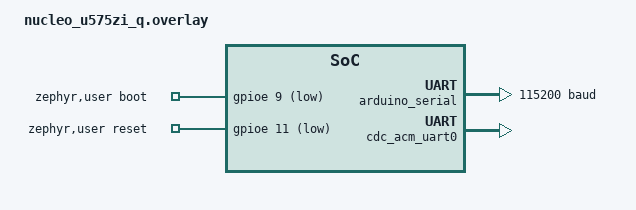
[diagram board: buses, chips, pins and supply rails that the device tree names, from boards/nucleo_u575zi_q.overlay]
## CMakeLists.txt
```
# SPDX-License-Identifier: Apache-2.0

cmake_minimum_required(VERSION 3.28.0)
find_package(Zephyr REQUIRED HINTS $ENV{ZEPHYR_BASE})
project(cdc_acm_bridge)

include(${ZEPHYR_BASE}/samples/subsys/usb/common/common.cmake)
FILE(GLOB app_sources src/*.c)
target_sources(app PRIVATE ${app_sources})
```

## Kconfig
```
# Copyright 2025 Google LLC
# SPDX-License-Identifier: Apache-2.0

# Source common USB sample options used to initialize new experimental USB
# device stack. The scope of these options is limited to USB samples in project
# tree, you cannot use them in your own application.
source "samples/subsys/usb/common/Kconfig.sample_usbd"

source "Kconfig.zephyr"
```

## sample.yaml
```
sample:
  name: CDC ACM USB bridge
tests:
  sample.usb.cdc-acm-bridge.arduino_serial:
    tags: usb
    build_only: true
    depends_on: usbd arduino_serial
  sample.usb.cdc-acm-bridge.two_devices:
    tags: usb
    build_only: true
    platform_allow:
      - rpi_pico
```

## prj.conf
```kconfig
CONFIG_UART_CONSOLE=n

CONFIG_USB_DEVICE_STACK_NEXT=y

CONFIG_SERIAL=y
CONFIG_UART_LINE_CTRL=y
CONFIG_UART_USE_RUNTIME_CONFIGURE=y
CONFIG_CDC_ACM_SERIAL_INITIALIZE_AT_BOOT=n

CONFIG_SAMPLE_USBD_PID=0x0001
CONFIG_SAMPLE_USBD_PRODUCT="USBD CDC ACM bridge sample"
```

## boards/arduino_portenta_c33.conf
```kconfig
# Drive the ESP32-C3 boot/reset straps from the CDC DTR/RTS lines.
CONFIG_GPIO=y

# Reliable flashing throughput: large CDC and bridge buffers so
# bursts from esptool are not dropped.
CONFIG_USBD_CDC_ACM_BUF_POOL_SIZE=4096
CONFIG_UART_BRIDGE_BUF_SIZE=4096
```

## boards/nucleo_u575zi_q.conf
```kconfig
# Drive the coprocessor boot/reset straps from the CDC DTR/RTS lines. Without
# CONFIG_GPIO the STM32 GPIO API is a no-op stub and the pins are never driven.
CONFIG_GPIO=y

## Reliable flashing throughput: large CDC and bridge buffers so
# bursts from QConn are not dropped.
CONFIG_USBD_CDC_ACM_BUF_POOL_SIZE=4096
CONFIG_UART_BRIDGE_BUF_SIZE=4096
```

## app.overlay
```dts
/*
 * Copyright 2025 Google LLC
 *
 * SPDX-License-Identifier: Apache-2.0
 */

/ {
	uart-bridge0 {
		compatible = "zephyr,uart-bridge";
		peers = <&cdc_acm_uart0 &arduino_serial>;
	};
};

&arduino_serial {
	status = "okay";
};

&zephyr_udc0 {
	cdc_acm_uart0: cdc_acm_uart0 {
		compatible = "zephyr,cdc-acm-uart";
		label = "Zephyr USB CDC-ACM";
	};
};
```

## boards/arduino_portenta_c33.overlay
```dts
/*
 * Copyright (C) Arduino s.r.l. and/or its affiliated companies
 *
 * SPDX-License-Identifier: Apache-2.0
 *
 * cdc_acm_bridge on Arduino Portenta C33: flash the onboard ESP32-C3
 * coprocessor from a host esptool over USB CDC-ACM.
 *
 * Bridges USB CDC-ACM <-> SCI8 (the ESP32-C3 UART) and drives the ESP boot
 * (P803, GPIO0/download strap) and reset/EN (P804) pins from the CDC DTR/RTS
 * lines, reproducing esptool's auto-download-reset circuit. The normal SPI
 * esp-hosted WiFi, the BT HCI link, and the download-strap regulator are
 * disabled so the UART and those pins are free for flashing.
 *
 * A boards/<board>.overlay replaces the sample's app.overlay, so the bridge and
 * CDC-ACM nodes are declared here too (reusing the board's board_cdc_acm_uart).
 */

#include <zephyr/dt-bindings/gpio/gpio.h>

/ {
	uart-bridge0 {
		compatible = "zephyr,uart-bridge";
		peers = <&board_cdc_acm_uart &uart8>;
	};

	zephyr,user {
		/* boot <- DTR, reset <- RTS; active-low (esptool default_reset).
		 *   boot-gpios  : P803 (ESP32-C3 GPIO0 / download strap)
		 *   reset-gpios : P804 (ESP32-C3 EN / reset)
		 */
		boot-gpios = <&ioport8 3 GPIO_ACTIVE_LOW>;
		reset-gpios = <&ioport8 4 GPIO_ACTIVE_LOW>;
	};

	/* P803 is also the esp-hosted download-strap regulator; disable it so the
	 * boot line above is free.
	 */
	download-esp32 {
		status = "disabled";
	};
};

/* ESP UART becomes a plain bridge peer: no BT HCI, no hardware flow control. */
&uart8 {
	/delete-property/ hw-flow-control;
};

&bt_hci_uart {
	status = "disabled";
};

/* Disable the SPI WiFi so it does not claim the reset/handshake pins. */
&spi1 {
	esp_hosted@1 {
		status = "disabled";
	};
};

/* Full-speed is ample for flashing (bulk 64-byte, ~1 MB/s) and avoids a
 * high-speed bulk-IN device->host stall in the RA USBHS UDC.
 */
&usbhs {
	maximum-speed = "full-speed";
};
```

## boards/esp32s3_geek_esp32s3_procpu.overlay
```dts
/*
 * Copyright (c) 2025 Chen Xingyu <hi@xingrz.me>
 * SPDX-License-Identifier: Apache-2.0
 */

/ {
	uart-bridge0 {
		compatible = "zephyr,uart-bridge";
		peers = <&cdc_acm_uart0 &uart0>;
	};
};

&usb_serial {
	status = "disabled";
};

&zephyr_udc0 {
	status = "okay";

	cdc_acm_uart0: cdc_acm_uart0 {
		compatible = "zephyr,cdc-acm-uart";
		label = "Zephyr USB CDC-ACM";
	};
};
```

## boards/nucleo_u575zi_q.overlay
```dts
/*
 * Copyright (C) Arduino s.r.l. and/or its affiliated companies
 *
 * SPDX-License-Identifier: Apache-2.0
 *
 * cdc_acm_bridge on NUCLEO-U575ZI-Q + X-NUCLEO-67W61M1 (ST67W611M1
 * coprocessor). Bridges USB CDC-ACM <-> LPUART1 (Arduino D0/D1, the module
 * firmware-update UART) and drives the module boot/reset straps from the CDC
 * DTR/RTS lines, so ST's QConn flashing tool can put the coprocessor into UART
 * ISP without a manual button press.
 *
 * A boards/<board>.overlay replaces the sample's app.overlay, so the bridge and
 * CDC-ACM nodes are declared here too.
 */

#include <zephyr/dt-bindings/gpio/gpio.h>

/ {
	uart-bridge0 {
		compatible = "zephyr,uart-bridge";
		peers = <&cdc_acm_uart0 &arduino_serial>;
	};

	zephyr,user {
		/* boot <- DTR, reset <- RTS; active-low matches the classic
		 * auto-download-reset circuit.
		 *   boot-gpios  : Arduino D6 = PE9  (module BOOT / GPIO0)
		 *   reset-gpios : Arduino D5 = PE11 (module CHIP_EN)
		 */
		boot-gpios = <&gpioe 9 GPIO_ACTIVE_LOW>;
		reset-gpios = <&gpioe 11 GPIO_ACTIVE_LOW>;
	};
};

&arduino_serial {
	/* Enable the hardware FIFO for reliable operation at higher baud rates;
	 * baud itself is set at runtime from the CDC line coding.
	 */
	current-speed = <115200>;
	fifo-enable;
	status = "okay";
};

&zephyr_udc0 {
	cdc_acm_uart0: cdc_acm_uart0 {
		compatible = "zephyr,cdc-acm-uart";
		label = "Zephyr USB CDC-ACM";
	};
};
```

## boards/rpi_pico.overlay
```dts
/ {
	uart-bridge0 {
		compatible = "zephyr,uart-bridge";
		peers = <&cdc_acm_uart0 &uart0>;
	};

	uart-bridge1 {
		compatible = "zephyr,uart-bridge";
		peers = <&cdc_acm_uart1 &uart1>;
	};
};

&pinctrl {
	uart1_default: uart1_default {
		group1 {
			pinmux = <UART1_TX_P4>;
		};

		group2 {
			pinmux = <UART1_RX_P5>;
			input-enable;
		};
	};
};

&uart1 {
	current-speed = <115200>;
	pinctrl-0 = <&uart1_default>;
	pinctrl-names = "default";
	status = "okay";
};

&zephyr_udc0 {
	cdc_acm_uart0: cdc_acm_uart0 {
		compatible = "zephyr,cdc-acm-uart";
		label = "Zephyr USB CDC-ACM uart0";
	};

	cdc_acm_uart1: cdc_acm_uart1 {
		compatible = "zephyr,cdc-acm-uart";
		label = "Zephyr USB CDC-ACM uart1";
	};
};
```

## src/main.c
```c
/*
 * Copyright 2025 Google LLC
 *
 * SPDX-License-Identifier: Apache-2.0
 */

#include <sample_usbd.h>

#include <stdio.h>
#include <string.h>
#include <zephyr/device.h>
#include <zephyr/drivers/uart/uart_bridge.h>
#include <zephyr/kernel.h>

#include <zephyr/usb/usb_device.h>
#include <zephyr/usb/usbd.h>
#include <zephyr/logging/log.h>
LOG_MODULE_REGISTER(cdc_acm_bridge, LOG_LEVEL_INF);

const struct device *const uart_dev = DEVICE_DT_GET_ONE(zephyr_cdc_acm_uart);

static struct usbd_context *sample_usbd;

const struct device *uart_bridges[] = {
	DT_FOREACH_STATUS_OKAY(zephyr_uart_bridge, DEVICE_DT_GET_COMMA)
};

static void sample_msg_cb(struct usbd_context *const ctx, const struct usbd_msg *msg)
{
	LOG_INF("USBD message: %s", usbd_msg_type_string(msg->type));

	if (usbd_can_detect_vbus(ctx)) {
		if (msg->type == USBD_MSG_VBUS_READY) {
			if (usbd_enable(ctx)) {
				LOG_ERR("Failed to enable device support");
			}
		}

		if (msg->type == USBD_MSG_VBUS_REMOVED) {
			if (usbd_disable(ctx)) {
				LOG_ERR("Failed to disable device support");
			}
		}
	}

	if (msg->type == USBD_MSG_CDC_ACM_LINE_CODING ||
	    msg->type == USBD_MSG_CDC_ACM_CONTROL_LINE_STATE) {
		for (uint8_t i = 0; i < ARRAY_SIZE(uart_bridges); i++) {
			/* update all bridges, non valid combinations are
			 * skipped automatically.
			 */
			uart_bridge_settings_update(msg->dev, uart_bridges[i]);
		}
	}
}

int main(void)
{
	int err;

	sample_usbd = sample_usbd_init_device(sample_msg_cb);
	if (sample_usbd == NULL) {
		LOG_ERR("Failed to initialize USB device");
		return -ENODEV;
	}

	if (!usbd_can_detect_vbus(sample_usbd)) {
		err = usbd_enable(sample_usbd);
		if (err) {
			LOG_ERR("Failed to enable device support");
			return err;
		}
	}

	LOG_INF("USB device support enabled");

	k_sleep(K_FOREVER);

	return 0;
}
```
